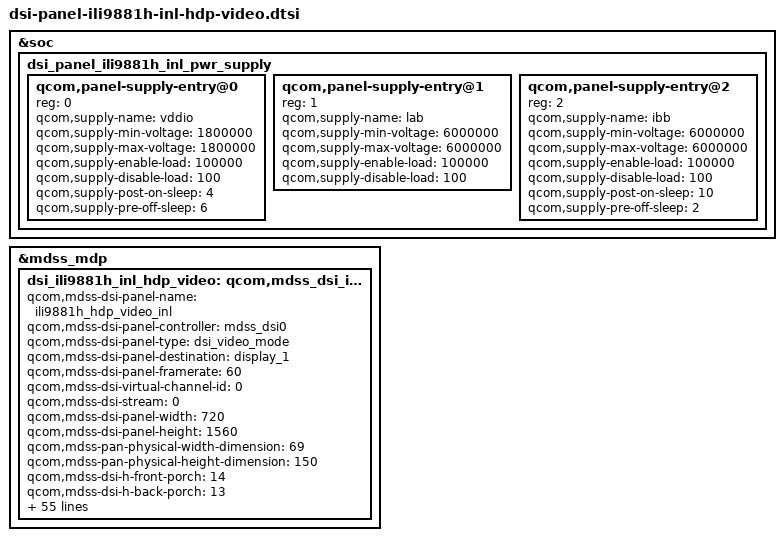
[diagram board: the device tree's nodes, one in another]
/* Copyright (c) 2013, The Linux Foundation. All rights reserved.
 *
 * This program is free software; you can redistribute it and/or modify
 * it under the terms of the GNU General Public License version 2 and
 * only version 2 as published by the Free Software Foundation.
 *
 * This program is distributed in the hope that it will be useful,
 * but WITHOUT ANY WARRANTY; without even the implied warranty of
 * MERCHANTABILITY or FITNESS FOR A PARTICULAR PURPOSE.  See the
 * GNU General Public License for more details.
 */

/*---------------------------------------------------------------------------
 * This file is autogenerated file using gcdb parser. Please do not edit it.
 * Update input XML file to add a new entry or update variable in this file
 * VERSION = "1.0"
 *---------------------------------------------------------------------------*/
&soc {
	dsi_panel_ili9881h_inl_pwr_supply: dsi_panel_ili9881h_inl_pwr_supply {
		#address-cells = <1>;
		#size-cells = <0>;

		qcom,panel-supply-entry@0 {
			reg = <0>;
			qcom,supply-name = "vddio";
			qcom,supply-min-voltage = <1800000>;
			qcom,supply-max-voltage = <1800000>;
			qcom,supply-enable-load = <100000>;
			qcom,supply-disable-load = <100>;
			qcom,supply-post-on-sleep = <4>;
			qcom,supply-pre-off-sleep = <6>;
		};
		qcom,panel-supply-entry@1 {
			reg = <1>;
			qcom,supply-name = "lab";
			qcom,supply-min-voltage = <6000000>;
			qcom,supply-max-voltage = <6000000>;
			qcom,supply-enable-load = <100000>;
			qcom,supply-disable-load = <100>;
		};
		qcom,panel-supply-entry@2 {
			reg = <2>;
			qcom,supply-name = "ibb";
			qcom,supply-min-voltage = <6000000>;
			qcom,supply-max-voltage = <6000000>;
			qcom,supply-enable-load = <100000>;
			qcom,supply-disable-load = <100>;
			qcom,supply-post-on-sleep = <10>;
			qcom,supply-pre-off-sleep = <2>;
		};
	};
};
&mdss_mdp {
	dsi_ili9881h_inl_hdp_video: qcom,mdss_dsi_ili9881h_inl_hdp_video {
		qcom,mdss-dsi-panel-name = "ili9881h_hdp_video_inl";
		qcom,mdss-dsi-panel-controller = <&mdss_dsi0>;
		qcom,mdss-dsi-panel-type = "dsi_video_mode";
		qcom,mdss-dsi-panel-destination = "display_1";
		qcom,mdss-dsi-panel-framerate = <60>;
		qcom,mdss-dsi-virtual-channel-id = <0>;
		qcom,mdss-dsi-stream = <0>;
		qcom,mdss-dsi-panel-width = <720>;
		qcom,mdss-dsi-panel-height = <1560>;
		qcom,mdss-pan-physical-width-dimension = <69>;
		qcom,mdss-pan-physical-height-dimension = <150>;
		qcom,mdss-dsi-h-front-porch = <14>;
		qcom,mdss-dsi-h-back-porch = <13>;
		qcom,mdss-dsi-h-pulse-width = <20>;
		qcom,mdss-dsi-h-sync-skew = <0>;
		qcom,mdss-dsi-v-back-porch = <16>;
		qcom,mdss-dsi-v-front-porch = <240>;
		qcom,mdss-dsi-v-pulse-width = <2>;
		qcom,mdss-dsi-h-left-border = <0>;
		qcom,mdss-dsi-h-right-border = <0>;
		qcom,mdss-dsi-v-top-border = <0>;
		qcom,mdss-dsi-v-bottom-border = <0>;
		qcom,mdss-dsi-bpp = <24>;
		qcom,mdss-dsi-color-order = "rgb_swap_rgb";
		qcom,mdss-dsi-underflow-color = <0xff>;
		qcom,mdss-dsi-border-color = <0>;
		qcom,mdss-dsi-on-command = [39 01 00 00 00 00 04 FF 98 81 01
								39 01 00 00 00 00 02 00 44
								39 01 00 00 00 00 02 01 13
								39 01 00 00 00 00 02 02 10
								39 01 00 00 00 00 02 03 20
								39 01 00 00 00 00 02 04 CA
								39 01 00 00 00 00 02 05 13
								39 01 00 00 00 00 02 06 10
								39 01 00 00 00 00 02 07 20
								39 01 00 00 00 00 02 08 82
								39 01 00 00 00 00 02 09 09
								39 01 00 00 00 00 02 0a b3
								39 01 00 00 00 00 02 0b 00
								39 01 00 00 00 00 02 0c 17
								39 01 00 00 00 00 02 0d 17
								39 01 00 00 00 00 02 0e 04
								39 01 00 00 00 00 02 0f 04
								39 01 00 00 00 00 02 10 0A
								39 01 00 00 00 00 02 11 0A
								39 01 00 00 00 00 02 12 09
								39 01 00 00 00 00 02 1E 0A
								39 01 00 00 00 00 02 1F 0A
								39 01 00 00 00 00 02 16 82
								39 01 00 00 00 00 02 17 09
								39 01 00 00 00 00 02 18 33
								39 01 00 00 00 00 02 19 00
								39 01 00 00 00 00 02 1a 17
								39 01 00 00 00 00 02 1b 17
								39 01 00 00 00 00 02 1c 04
								39 01 00 00 00 00 02 1d 04
								39 01 00 00 00 00 02 20 09
								39 01 00 00 00 00 02 24 42
								39 01 00 00 00 00 02 25 0B
								39 01 00 00 00 00 02 26 10
								39 01 00 00 00 00 02 27 20
								39 01 00 00 00 00 02 2c 34
								39 01 00 00 00 00 02 31 21
								39 01 00 00 00 00 02 32 0D
								39 01 00 00 00 00 02 33 07
								39 01 00 00 00 00 02 34 2a
								39 01 00 00 00 00 02 35 28
								39 01 00 00 00 00 02 36 29
								39 01 00 00 00 00 02 37 11
								39 01 00 00 00 00 02 38 13
								39 01 00 00 00 00 02 39 15
								39 01 00 00 00 00 02 3a 17
								39 01 00 00 00 00 02 3b 19
								39 01 00 00 00 00 02 3c 1b
								39 01 00 00 00 00 02 3d 09
								39 01 00 00 00 00 02 3e 07
								39 01 00 00 00 00 02 3f 07
								39 01 00 00 00 00 02 40 07
								39 01 00 00 00 00 02 41 07
								39 01 00 00 00 00 02 42 07
								39 01 00 00 00 00 02 43 07
								39 01 00 00 00 00 02 44 07
								39 01 00 00 00 00 02 45 07
								39 01 00 00 00 00 02 46 07
								39 01 00 00 00 00 02 47 20
								39 01 00 00 00 00 02 48 0C
								39 01 00 00 00 00 02 49 07
								39 01 00 00 00 00 02 4a 2a
								39 01 00 00 00 00 02 4b 28
								39 01 00 00 00 00 02 4c 29
								39 01 00 00 00 00 02 4d 10
								39 01 00 00 00 00 02 4e 12
								39 01 00 00 00 00 02 4f 14
								39 01 00 00 00 00 02 50 16
								39 01 00 00 00 00 02 51 18
								39 01 00 00 00 00 02 52 1a
								39 01 00 00 00 00 02 53 08
								39 01 00 00 00 00 02 54 07
								39 01 00 00 00 00 02 55 07
								39 01 00 00 00 00 02 56 07
								39 01 00 00 00 00 02 57 07
								39 01 00 00 00 00 02 58 07
								39 01 00 00 00 00 02 59 07
								39 01 00 00 00 00 02 5a 07
								39 01 00 00 00 00 02 5b 07
								39 01 00 00 00 00 02 5c 07
								39 01 00 00 00 00 02 61 08
								39 01 00 00 00 00 02 62 0C
								39 01 00 00 00 00 02 63 07
								39 01 00 00 00 00 02 64 2a
								39 01 00 00 00 00 02 65 28
								39 01 00 00 00 00 02 66 29
								39 01 00 00 00 00 02 67 1A
								39 01 00 00 00 00 02 68 18
								39 01 00 00 00 00 02 69 16
								39 01 00 00 00 00 02 6A 14
								39 01 00 00 00 00 02 6B 12
								39 01 00 00 00 00 02 6C 10
								39 01 00 00 00 00 02 6D 20
								39 01 00 00 00 00 02 6E 07
								39 01 00 00 00 00 02 6F 07
								39 01 00 00 00 00 02 70 07
								39 01 00 00 00 00 02 71 07
								39 01 00 00 00 00 02 72 07
								39 01 00 00 00 00 02 73 07
								39 01 00 00 00 00 02 74 07
								39 01 00 00 00 00 02 75 07
								39 01 00 00 00 00 02 76 07
								39 01 00 00 00 00 02 77 09
								39 01 00 00 00 00 02 78 0D
								39 01 00 00 00 00 02 79 07
								39 01 00 00 00 00 02 7A 2a
								39 01 00 00 00 00 02 7B 28
								39 01 00 00 00 00 02 7C 29
								39 01 00 00 00 00 02 7D 1B
								39 01 00 00 00 00 02 7E 19
								39 01 00 00 00 00 02 7F 17
								39 01 00 00 00 00 02 80 15
								39 01 00 00 00 00 02 81 13
								39 01 00 00 00 00 02 82 11
								39 01 00 00 00 00 02 83 21
								39 01 00 00 00 00 02 84 07
								39 01 00 00 00 00 02 85 07
								39 01 00 00 00 00 02 86 07
								39 01 00 00 00 00 02 87 07
								39 01 00 00 00 00 02 88 07
								39 01 00 00 00 00 02 89 07
								39 01 00 00 00 00 02 8A 07
								39 01 00 00 00 00 02 8B 07
								39 01 00 00 00 00 02 8C 07
								39 01 00 00 00 00 02 A0 01
								39 01 00 00 00 00 02 A1 00
								39 01 00 00 00 00 02 A2 2A
								39 01 00 00 00 00 02 A3 00
								39 01 00 00 00 00 02 A4 2A
								39 01 00 00 00 00 02 A5 05
								39 01 00 00 00 00 02 A6 2A
								39 01 00 00 00 00 02 A7 02
								39 01 00 00 00 00 02 A8 02
								39 01 00 00 00 00 02 A9 28
								39 01 00 00 00 00 02 Aa 28
								39 01 00 00 00 00 02 Ab 02
								39 01 00 00 00 00 02 Ac 02
								39 01 00 00 00 00 02 Ad 28
								39 01 00 00 00 00 02 Ae 28
								39 01 00 00 00 00 02 b0 33
								39 01 00 00 00 00 02 b1 33
								39 01 00 00 00 00 02 b2 00
								39 01 00 00 00 00 02 b9 40
								39 01 00 00 00 00 02 c3 ff
								39 01 00 00 00 00 02 ca 44
								39 01 00 00 00 00 02 d0 01
								39 01 00 00 00 00 02 d1 00
								39 01 00 00 00 00 02 dc 37
								39 01 00 00 00 00 02 dd 42
								39 01 00 00 00 00 02 e2 00
								39 01 00 00 00 00 02 e6 22
								39 01 00 00 00 00 02 e7 54
								39 01 00 00 00 00 02 ED 00
								39 01 00 00 00 00 04 FF 98 81 02
								39 01 00 00 00 00 02 40 42
								39 01 00 00 00 00 02 4B 5A
								39 01 00 00 00 00 02 06 90
								39 01 00 00 00 00 02 01 30
								39 01 00 00 00 00 02 4D 4E
								39 01 00 00 00 00 02 4E 00
								39 01 00 00 00 00 02 1A 48
								39 01 00 00 00 00 02 52 48
								39 01 00 00 00 00 02 57 48
								39 01 00 00 00 00 04 FF 98 81 05
								39 01 00 00 00 00 02 03 01
								39 01 00 00 00 00 02 04 09
								39 01 00 00 00 00 02 63 9C
								39 01 00 00 00 00 02 64 9C
								39 01 00 00 00 00 02 68 B5
								39 01 00 00 00 00 02 69 BB
								39 01 00 00 00 00 02 6A A1
								39 01 00 00 00 00 02 6B 93
								39 01 00 00 00 00 02 E0 03
								39 01 00 00 00 00 02 85 7F
								39 01 00 00 00 00 02 E5 6D
								39 01 00 00 00 00 02 E6 40
								39 01 00 00 00 00 02 E7 D8
								39 01 00 00 00 00 02 E8 D8
								39 01 00 00 00 00 02 E9 A5
								39 01 00 00 00 00 02 C0 01
								39 01 00 00 00 00 02 C1 00
								39 01 00 00 00 00 02 C2 01
								39 01 00 00 00 00 02 C3 00
								39 01 00 00 00 00 02 C4 01
								39 01 00 00 00 00 02 C5 00
								39 01 00 00 00 00 02 C6 01
								39 01 00 00 00 00 02 C7 00
								39 01 00 00 00 00 02 C8 B5
								39 01 00 00 00 00 02 C9 B5
								39 01 00 00 00 00 02 CA 79
								39 01 00 00 00 00 02 CB 79
								39 01 00 00 00 00 02 CC A1
								39 01 00 00 00 00 02 CD A1
								39 01 00 00 00 00 02 CE A1
								39 01 00 00 00 00 02 CF A1
								39 01 00 00 00 00 02 D0 BB
								39 01 00 00 00 00 02 D1 BB
								39 01 00 00 00 00 02 D2 7F
								39 01 00 00 00 00 02 D3 7F
								39 01 00 00 00 00 02 D4 93
								39 01 00 00 00 00 02 D5 93
								39 01 00 00 00 00 02 D6 93
								39 01 00 00 00 00 02 D7 93
								39 01 00 00 00 00 04 FF 98 81 06
								39 01 00 00 00 00 02 11 03
								39 01 00 00 00 00 02 13 45
								39 01 00 00 00 00 02 14 41
								39 01 00 00 00 00 02 15 F1
								39 01 00 00 00 00 02 16 40
								39 01 00 00 00 00 02 17 FF
								39 01 00 00 00 00 02 18 00
								39 01 00 00 00 00 02 94 00
								39 01 00 00 00 00 02 48 0F
								39 01 00 00 00 00 02 4D 80
								39 01 00 00 00 00 02 4E 40
								39 01 00 00 00 00 02 C7 05
								39 01 00 00 00 00 04 FF 98 81 06
								39 01 00 00 00 00 02 D6 87
								39 01 00 00 00 00 02 27 FF
								39 01 00 00 00 00 02 28 20
								39 01 00 00 00 00 02 2E 01
								39 01 00 00 00 00 02 C0 0B
								39 01 00 00 00 00 02 C1 03
								39 01 00 00 00 00 02 C2 04
								39 01 00 00 00 00 02 7C 40
								39 01 00 00 00 00 02 DD 10
								39 01 00 00 00 00 02 12 00
								39 01 00 00 00 00 02 94 01
								39 01 00 00 00 00 02 D5 54
								39 01 00 00 00 00 02 58 24
								39 01 00 00 00 00 04 FF 98 81 0E
								39 01 00 00 00 00 02 00 A0
								39 01 00 00 00 00 02 01 28
								39 01 00 00 00 00 02 02 10
								39 01 00 00 00 00 02 13 10
								39 01 00 00 00 00 02 41 50
								39 01 00 00 00 00 02 20 07
								39 01 00 00 00 00 02 29 BE
								39 01 00 00 00 00 02 25 0A
								39 01 00 00 00 00 02 26 23
								39 01 00 00 00 00 02 2D 95
								39 01 00 00 00 00 02 40 07
								39 01 00 00 00 00 02 49 BE
								39 01 00 00 00 00 02 45 0A
								39 01 00 00 00 00 02 46 23
								39 01 00 00 00 00 02 4D 96
								39 01 00 00 00 00 04 FF 98 81 0E
								39 01 00 00 00 00 02 C0 11
								39 01 00 00 00 00 02 C1 80
								39 01 00 00 00 00 02 C2 08
								39 01 00 00 00 00 02 C3 01
								39 01 00 00 00 00 02 C4 44
								39 01 00 00 00 00 02 C5 44
								39 01 00 00 00 00 02 C6 44
								39 01 00 00 00 00 02 C7 40
								39 01 00 00 00 00 02 D0 36
								39 01 00 00 00 00 02 D1 00
								39 01 00 00 00 00 02 D2 00
								39 01 00 00 00 00 02 D3 95
								39 01 00 00 00 00 02 D4 75
								39 01 00 00 00 00 02 D5 75
								39 01 00 00 00 00 02 D6 75
								39 01 00 00 00 00 02 D7 75
								39 01 00 00 00 00 02 D8 75
								39 01 00 00 00 00 02 D9 80
								39 01 00 00 00 00 02 DA 44
								39 01 00 00 00 00 02 DB 44
								39 01 00 00 00 00 02 DC 44
								39 01 00 00 00 00 02 DD 44
								39 01 00 00 00 00 02 E1 08
								39 01 00 00 00 00 02 E2 19
								39 01 00 00 00 00 02 E3 10
								39 01 00 00 00 00 02 43 60
								39 01 00 00 00 00 04 FF 98 81 07
								39 01 00 00 00 00 02 0F 02
								39 01 00 00 00 00 04 FF 98 81 08
								39 01 00 00 00 00 1C E0 00 24 4D 6F 9F 50 CA EE 1B 41 95 7F B4 E4 13 AA 45 80 A5 D3 FE FA 2B 66 96 03 EC
								39 01 00 00 00 00 1C E1 00 24 4D 6F 9F 50 CA EE 1B 41 95 7F B4 E4 13 AA 45 80 A5 D3 FE FA 2B 66 96 03 EC
								39 01 00 00 00 00 04 FF 98 81 06
								39 01 00 00 00 00 02 06 C4
								39 01 00 00 00 00 04 FF 98 81 03
								39 01 00 00 00 00 02 83 30
								39 01 00 00 00 00 02 84 00
								39 01 00 00 00 00 02 90 0C
								39 01 00 00 00 00 02 91 F1
								39 01 00 00 00 00 02 92 16
								39 01 00 00 00 00 02 93 F6
								39 01 00 00 00 00 04 FF 98 81 00
								39 01 00 00 00 00 03 51 00 00
								39 01 00 00 00 00 02 53 24
								39 01 00 00 00 00 02 55 00  // cabc function, now it close, if want open set 55 01
								39 01 00 00 00 00 03 68 04 00
								39 01 00 00 00 00 04 FF 98 81 00
								39 01 00 00 00 00 02 35 00
								39 01 00 00 78 00 02 11 00
								39 01 00 00 14 00 02 29 00
								];
		qcom,mdss-dsi-off-command = [
					05 01 00 00 14 00 02 28 00
					05 01 00 00 C8 00 02 10 00];
		qcom,mdss-dsi-on-command-state = "dsi_lp_mode";
		qcom,mdss-dsi-off-command-state = "dsi_lp_mode";
		qcom,mdss-dsi-h-sync-pulse = <1>;
		qcom,mdss-dsi-traffic-mode = "burst_mode";
		// qcom,mdss-dsi-lane-map = "lane_map_3012";
		qcom,mdss-dsi-bllp-eof-power-mode;
		qcom,mdss-dsi-bllp-power-mode;
		qcom,mdss-dsi-lane-0-state;
		qcom,mdss-dsi-lane-1-state;
		qcom,mdss-dsi-lane-2-state;
		qcom,mdss-dsi-panel-timings-phy-v2 = [21 1E 06 07 04 03 04 a0
						21 1E 06 07 04 03 04 a0
						21 1E 06 07 04 03 04 a0
						21 1E 06 07 04 03 04 a0
						21 14 06 07 04 03 04 a0];
		qcom,mdss-dsi-t-clk-post = <0x0C>;
		qcom,mdss-dsi-t-clk-pre = <0x27>;
		qcom,mdss-dsi-bl-pmic-control-type = "bl_ctrl_dcs";
		qcom,mdss-dsi-bl-min-level = <1>;
		qcom,mdss-dsi-bl-max-level = <255>;
		ss,blmap-size = <256>;
		ss,blmap = < 0 1 1 1 1 1 1 1 1 1
					1 1 2 3 4 5 6 7 8 9
					10 11 12 13 14 15 16 17 18 19
					20 21 22 23 24 25 26 27 28 29
					30 31 32 33 34 35 36 37 38 39
					40 41 42 43 44 45 46 47 48 49
					50 51 52 53 54 55 56 57 58 59
					60 61 62 63 64 65 66 67 68 69
					70 71 72 73 74 75 76 77 78 79
					80 81 82 83 84 85 86 87 88 89
					90 91 92 93 94 95 96 97 98 99
					100 101 102 103 104 105 106 107 108 109
					110 111 112 113 114 115 116 117 118 119
					120 121 122 123 124 125 126 127 128 129
					130 131 132 133 134 135 136 137 138 139
					140 141 142 143 144 145 146 147 148 149
					150 151 152 153 154 155 156 157 158 159
					160 161 162 163 164 165 166 167 168 169
					170 171 172 173 174 175 176 177 178 179
					180 181 182 183 184 185 186 187 188 189
					190 191 192 193 194 195 196 197 198 199
					200 201 202 203 204 205 206 207 208 209
					210 211 212 213 214 215 216 217 218 219
					220 221 222 223 224 225 226 227 228 229
					230 231 232 233 234 236 238 240 242 244
					246 248 250 252 254 255>;
		qcom,mdss-dsi-dma-trigger = "trigger_sw";
		qcom,mdss-dsi-mdp-trigger = "none";
		qcom,mdss-dsi-lp11-init;
		qcom,mdss-dsi-init-delay-us = <5000>;
		qcom,mdss-dsi-reset-sequence = <1 1>, <0 1>, <1 10>;
		//Chk 40244, wangcong.wt, modify ,2020/11/30, open ESD recovery
		qcom,esd-check-enabled;
		qcom,mdss-dsi-panel-status-command = [06 01 00 01 05 00 02 0A 08];
		qcom,mdss-dsi-panel-status-command-state = "dsi_lp_mode";
		qcom,mdss-dsi-panel-status-check-mode = "reg_read";
		qcom,mdss-dsi-panel-status-valid-params = <1>;
		qcom,mdss-dsi-panel-status-value = <0x9C>;
		qcom,mdss-dsi-panel-status-read-length = <1>;
		qcom,mdss-dsi-tx-eot-append;
		qcom,panel-supply-entries = <&dsi_panel_ili9881h_inl_pwr_supply>;
	};
};
